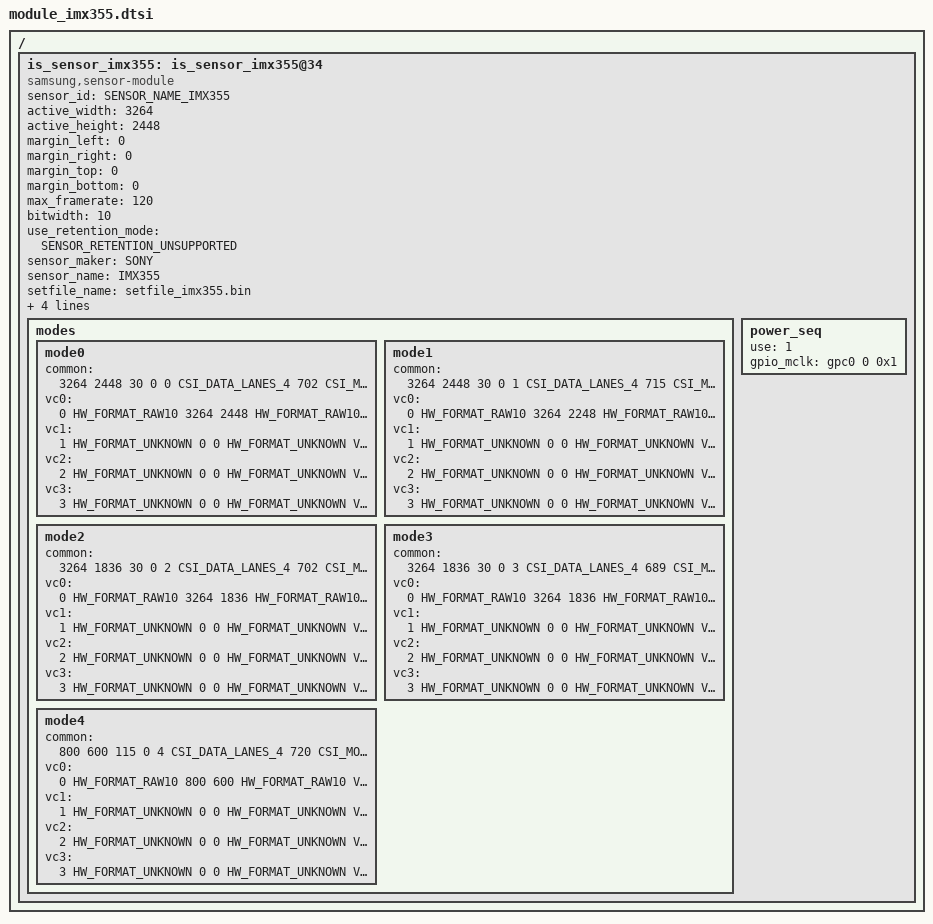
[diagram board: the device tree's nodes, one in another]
/*
 * SAMSUNG EXYNOSxxxx board camera device tree source
 *
 * Copyright (c) 2021 Samsung Electronics Co., Ltd.
 *		http://www.samsung.com
 *
 * This program is free software; you can redistribute it and/or modify
 * it under the terms of the GNU General Public License version 2 as
 * published by the Free Software Foundation.
 */

#include <dt-bindings/camera/exynos_is_dt.h>
#ifndef USE_VENDOR_PWR_PIN_NAME
#define IMX355_AVDD		<>
#define IMX355_DVDD		<>
#define IMX355_IOVDD	<>
#endif

/ {
	fragment@camera {
		target-path = "/";
		__overlay__ {
			is_sensor_imx355: is_sensor_imx355@34 {
				compatible = "samsung,sensor-module";

				/* common */
				sensor_id = <SENSOR_NAME_IMX355>;
				active_width = <3264>;
				active_height = <2448>;
				margin_left = <0>;
				margin_right = <0>;
				margin_top = <0>;
				margin_bottom = <0>;
				max_framerate = <120>;
				bitwidth = <10>;
				use_retention_mode = <SENSOR_RETENTION_UNSUPPORTED>;
				sensor_maker = "SONY";
				sensor_name = "IMX355";
				setfile_name = "setfile_imx355.bin";

				imx355_iovdd-supply = IMX355_IOVDD;
				imx355_dvdd-supply = IMX355_DVDD;
				imx355_avdd-supply = IMX355_AVDD;
				imx355_af-supply = RCAM_AF_VDD;

				status = "okay";

				/* sensor modes */
				modes {
					/* common = <width, height, fps, settle, mode, lane, speed, interleave, lrte, pd_mode> */
					/* vcX = <map, hwformat, width, height, hwformat, type, width, height> */
					mode0 {/* A-1 */
						common = <3264 2448 30 0 0 CSI_DATA_LANES_4 702 CSI_MODE_VC_ONLY LRTE_DISABLE PD_NONE EX_NONE>;
						vc0 = </* in */ 0 HW_FORMAT_RAW10 3264 2448    /* out */ HW_FORMAT_RAW10 VC_NOTHING 0 0>;
						vc1 = </* in */ 1 HW_FORMAT_UNKNOWN 0 0        /* out */ HW_FORMAT_UNKNOWN VC_NOTHING 0 0>;
						vc2 = </* in */ 2 HW_FORMAT_UNKNOWN 0 0        /* out */ HW_FORMAT_UNKNOWN VC_NOTHING 0 0>; 
						vc3 = </* in */ 3 HW_FORMAT_UNKNOWN 0 0        /* out */ HW_FORMAT_UNKNOWN VC_NOTHING 0 0>;
					};
					mode1 {/* N-1 */
						common = <3264 2448 30 0 1 CSI_DATA_LANES_4 715 CSI_MODE_VC_ONLY LRTE_DISABLE PD_NONE EX_NONE>;
						vc0 = </* in */ 0 HW_FORMAT_RAW10 3264 2248    /* out */ HW_FORMAT_RAW10 VC_NOTHING 0 0>;
						vc1 = </* in */ 1 HW_FORMAT_UNKNOWN 0 0        /* out */ HW_FORMAT_UNKNOWN VC_NOTHING 0 0>;
						vc2 = </* in */ 2 HW_FORMAT_UNKNOWN 0 0        /* out */ HW_FORMAT_UNKNOWN VC_NOTHING 0 0>;
						vc3 = </* in */ 3 HW_FORMAT_UNKNOWN 0 0        /* out */ HW_FORMAT_UNKNOWN VC_NOTHING 0 0>;
					};
					mode2 {/* K-1 */
						common = <3264 1836 30 0 2 CSI_DATA_LANES_4 702 CSI_MODE_VC_ONLY LRTE_DISABLE PD_NONE EX_NONE>;
						vc0 = </* in */ 0 HW_FORMAT_RAW10 3264 1836    /* out */ HW_FORMAT_RAW10 VC_NOTHING 3264 1836>;
						vc1 = </* in */ 1 HW_FORMAT_UNKNOWN 0 0        /* out */ HW_FORMAT_UNKNOWN VC_NOTHING 0 0>;
						vc2 = </* in */ 2 HW_FORMAT_UNKNOWN 0 0        /* out */ HW_FORMAT_UNKNOWN VC_NOTHING 0 0>;
						vc3 = </* in */ 3 HW_FORMAT_UNKNOWN 0 0        /* out */ HW_FORMAT_UNKNOWN VC_NOTHING 0 0>;
					};
					mode3 {/* J-1 */
						common = <3264 1836 30 0 3 CSI_DATA_LANES_4 689 CSI_MODE_VC_ONLY LRTE_DISABLE PD_NONE EX_NONE>;
						vc0 = </* in */ 0 HW_FORMAT_RAW10 3264 1836    /* out */ HW_FORMAT_RAW10 VC_NOTHING 3264 1836>;
						vc1 = </* in */ 1 HW_FORMAT_UNKNOWN 0 0        /* out */ HW_FORMAT_UNKNOWN VC_NOTHING 0 0>;
						vc2 = </* in */ 2 HW_FORMAT_UNKNOWN 0 0        /* out */ HW_FORMAT_UNKNOWN VC_NOTHING 0 0>;
						vc3 = </* in */ 3 HW_FORMAT_UNKNOWN 0 0        /* out */ HW_FORMAT_UNKNOWN VC_NOTHING 0 0>;
					};
					mode4 {/* M-1 */
						common = <800 600 115 0 4 CSI_DATA_LANES_4 720 CSI_MODE_VC_ONLY LRTE_DISABLE PD_NONE EX_NONE>;
						vc0 = </* in */ 0 HW_FORMAT_RAW10 800 600    /* out */ HW_FORMAT_RAW10 VC_NOTHING 800 600>;
						vc1 = </* in */ 1 HW_FORMAT_UNKNOWN 0 0        /* out */ HW_FORMAT_UNKNOWN VC_NOTHING 0 0>;
						vc2 = </* in */ 2 HW_FORMAT_UNKNOWN 0 0        /* out */ HW_FORMAT_UNKNOWN VC_NOTHING 0 0>;
						vc3 = </* in */ 3 HW_FORMAT_UNKNOWN 0 0        /* out */ HW_FORMAT_UNKNOWN VC_NOTHING 0 0>;
					};
				};

				power_seq {
					use = <1>;
					gpio_mclk = <&gpc0 0 0x1>;
#if 0
					scenario_normal_on {
						sensor_scenario = <SENSOR_SCENARIO_NORMAL>;
						gpio_scenario = <GPIO_SCENARIO_ON>;
						/* A start node number should be over the 10 for reserved number 0~9. */
						/* pname = "name"; pin = <act value delay voltage>; gpio = <gpx# # 0x1>; */
						10 { pname = "sen_rst_low"; pin = <PIN_OUTPUT 0 0>; gpio = <&gpg2 2 0x1>; };
						20 { pname = "IMX355_IOVDD"; pin = <PIN_OUTPUT 1 0>; gpio = <&gpg1 6 0x1>; };
						30 { pname = "IMX355_DVDD"; pin = <PIN_OUTPUT 1 0>; gpio = <&gpg1 7 0x1>; };
						40 { pname = "IMX355_AVDD"; pin = <PIN_OUTPUT 1 0>; gpio = <&gpg2 5 0x1>; };
						50 { pname = "on_i2c"; pin = <PIN_I2C 1 0>; };
						60 { pname = "sen_rst_high"; pin = <PIN_OUTPUT 1 1000>; gpio = <&gpg2 2 0x1>; };
						70 { pname = "pin"; pin = <PIN_FUNCTION 2 1000>; };
						80 { pname = "MCLK"; pin = <PIN_MCLK 1 12000>; gpio = <&gpc0 0 0x1>; };
					};

					scenario_normal_off {
						sensor_scenario = <SENSOR_SCENARIO_NORMAL>;
						gpio_scenario = <GPIO_SCENARIO_OFF>;
						/* A start node number should be over the 10 for reserved number 0~9. */
						/* pname = "name"; pin = <act value delay voltage>; gpio = <gpx# # 0x1>; */
						10 { pname = "sen_rst_low"; pin = <PIN_OUTPUT 0 0>; gpio = <&gpg2 2 0x1>; };
						20 { pname = "off_i2c"; pin = <PIN_I2C 0 0>; };
						30 { pname = "IMX355_AVDD"; pin = <PIN_OUTPUT 0 0>; gpio = <&gpg2 5 0x1>; };
						40 { pname = "IMX355_DVDD"; pin = <PIN_OUTPUT 0 0>; gpio = <&gpg1 7 0x1>; };
						50 { pname = "IMX355_IOVDD"; pin = <PIN_OUTPUT 0 0>; gpio = <&gpg1 6 0x1>; };
						60 { pname = "MCLK"; pin = <PIN_MCLK 0 0>; gpio = <&gpc0 0 0x1>; };
						70 { pname = "pin"; pin = <PIN_FUNCTION 0 0>; };
						80 { pname = "pin"; pin = <PIN_FUNCTION 1 0>; };
						90 { pname = "pin"; pin = <PIN_FUNCTION 0 0>; };
					};

					scenario_read_rom_on {
						sensor_scenario = <SENSOR_SCENARIO_READ_ROM>;
						gpio_scenario = <GPIO_SCENARIO_ON>;
					};

					scenario_read_rom_off {
						sensor_scenario = <SENSOR_SCENARIO_READ_ROM>;
						gpio_scenario = <GPIO_SCENARIO_OFF>;
					};
#endif
				};
			};
		}; /* end of __overlay__ */
	}; /* end of fragment */
}; /* end of root */
